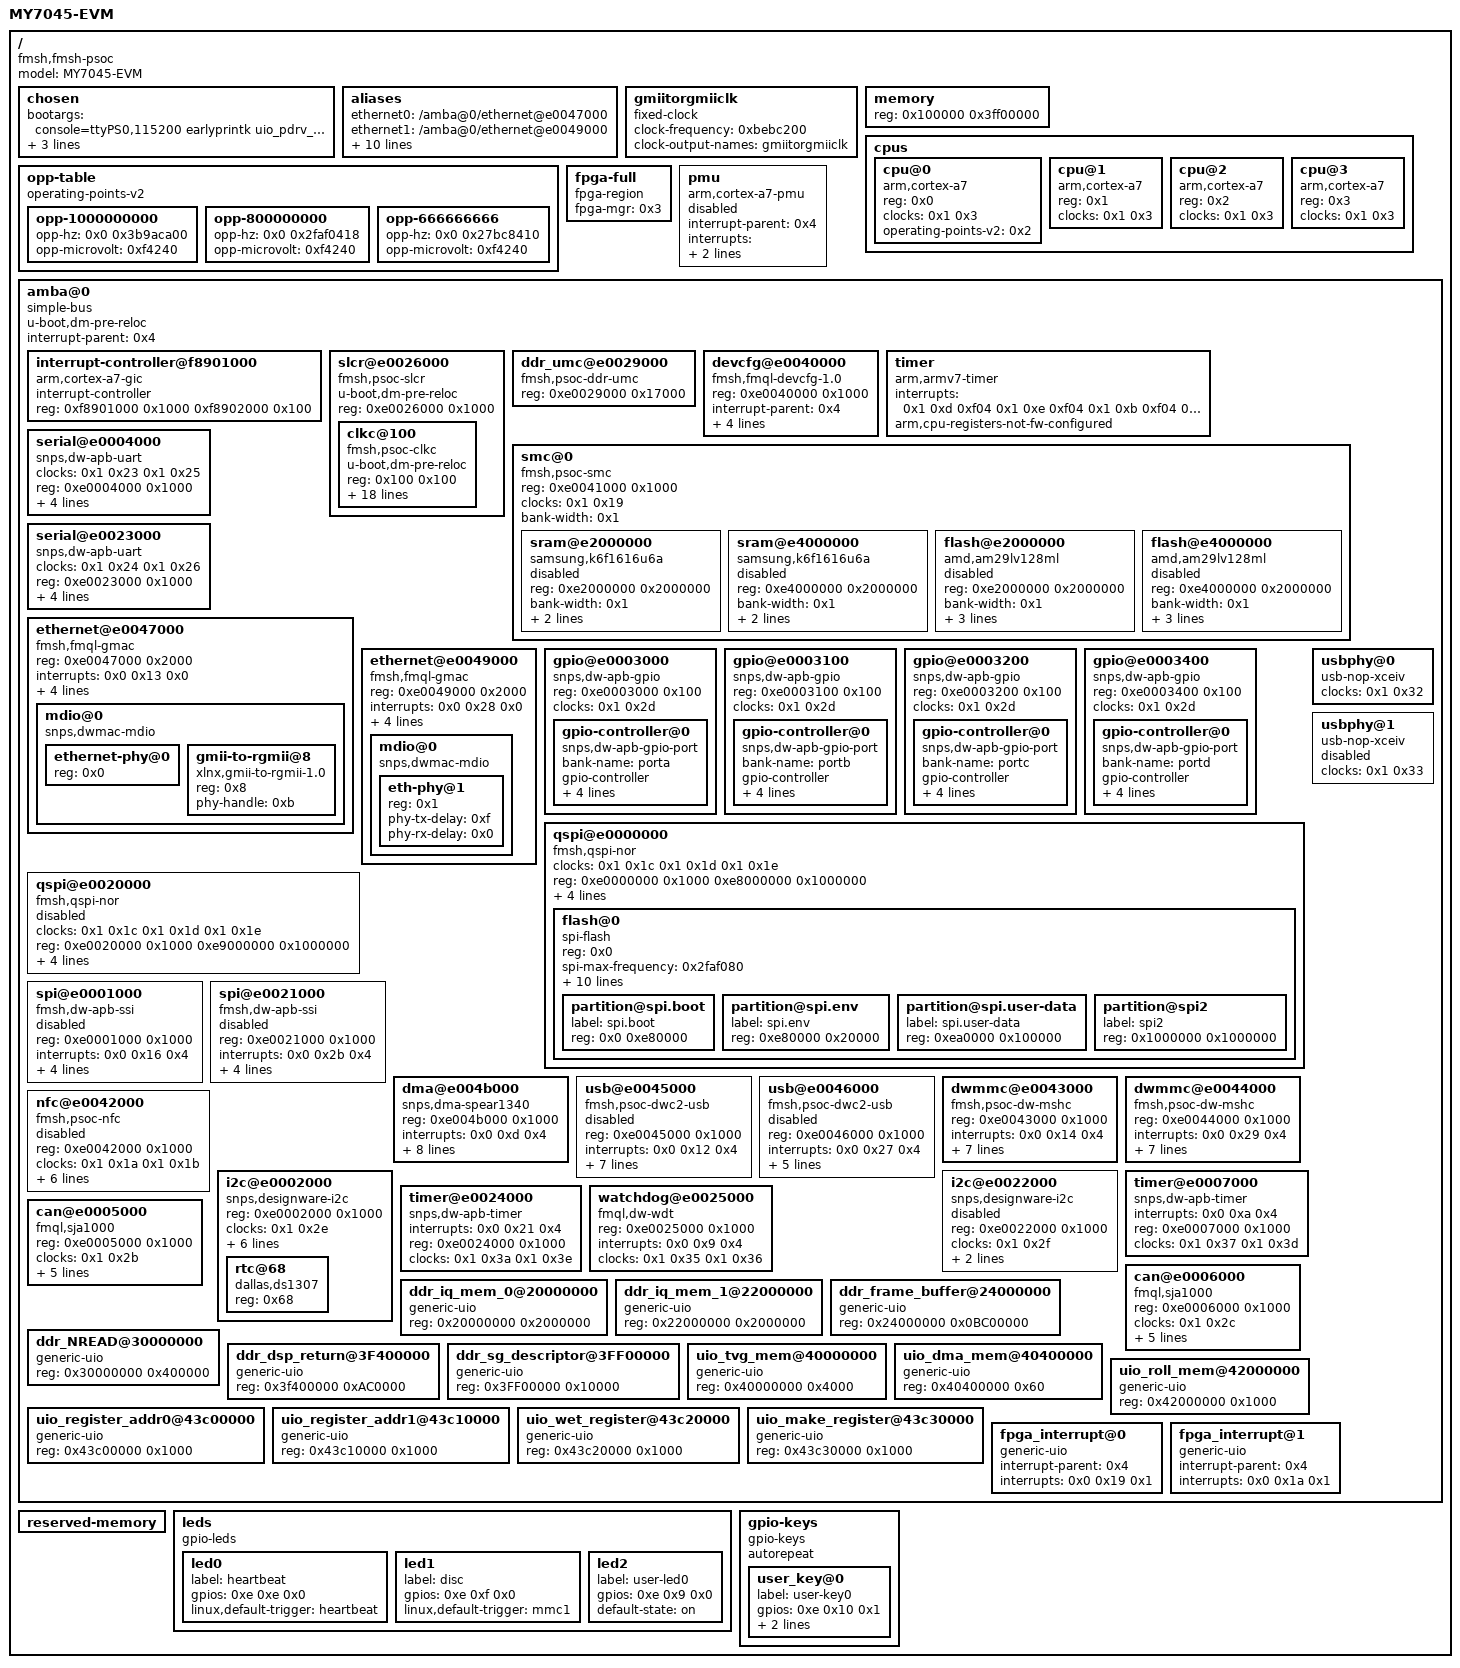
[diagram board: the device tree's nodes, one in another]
/dts-v1/;

/ {
	#address-cells = <0x1>;
	#size-cells = <0x1>;
	model = "MY7045-EVM";
	compatible = "fmsh,fmsh-psoc";

	chosen {
		bootargs = "console=ttyPS0,115200 earlyprintk uio_pdrv_genirq.of_id=generic-uio loglevel=8 root=/dev/mmcblk0p2 rw";
		stdout-path = "serial0:115200n8";
		linux,initrd-start = <0x12000000>;
		linux,initrd-end = <0x12800000>;
	};

	aliases {
		ethernet0 = "/amba@0/ethernet@e0047000";
		ethernet1 = "/amba@0/ethernet@e0049000";
		serial0 = "/amba@0/serial@e0023000";
		serial1 = "/amba@0/serial@e0004000";
		spi0 = "/amba@0/qspi@e0000000";
		spi1 = "/amba@0/qspi@e0020000";
		spi2 = "/amba@0/spi@e0001000";
		spi3 = "/amba@0/spi@e0021000";
		mmc0 = "/amba@0/dwmmc@e0043000";
		mmc1 = "/amba@0/dwmmc@e0044000";
		i2c0 = "/amba@0/i2c@e0002000";
		i2c1 = "/amba@0/i2c@e0022000";
	};

	gmiitorgmiiclk {
		compatible = "fixed-clock";
		#clock-cells = <0x0>;
		clock-frequency = <0xbebc200>;
		clock-output-names = "gmiitorgmiiclk";
	};

	memory {
		device_type = "memory";
		reg = <0x100000 0x3ff00000>;
	};

	cpus {
		#address-cells = <0x1>;
		#size-cells = <0x0>;

		cpu@0 {
			compatible = "arm,cortex-a7";
			device_type = "cpu";
			reg = <0x0>;
			clocks = <0x1 0x3>;
			operating-points-v2 = <0x2>;
			linux,phandle = <0x5>;
			phandle = <0x5>;
		};

		cpu@1 {
			compatible = "arm,cortex-a7";
			device_type = "cpu";
			reg = <0x1>;
			clocks = <0x1 0x3>;
			linux,phandle = <0x6>;
			phandle = <0x6>;
		};

		cpu@2 {
			compatible = "arm,cortex-a7";
			device_type = "cpu";
			reg = <0x2>;
			clocks = <0x1 0x3>;
			linux,phandle = <0x7>;
			phandle = <0x7>;
		};

		cpu@3 {
			compatible = "arm,cortex-a7";
			device_type = "cpu";
			reg = <0x3>;
			clocks = <0x1 0x3>;
			linux,phandle = <0x8>;
			phandle = <0x8>;
		};
	};

	opp-table {
		compatible = "operating-points-v2";
		linux,phandle = <0x2>;
		phandle = <0x2>;

		opp-1000000000 {
			opp-hz = <0x0 0x3b9aca00>;
			opp-microvolt = <0xf4240>;
		};

		opp-800000000 {
			opp-hz = <0x0 0x2faf0418>;
			opp-microvolt = <0xf4240>;
		};

		opp-666666666 {
			opp-hz = <0x0 0x27bc8410>;
			opp-microvolt = <0xf4240>;
		};
	};

	fpga-full {
		compatible = "fpga-region";
		fpga-mgr = <0x3>;
		#address-cells = <0x1>;
		#size-cells = <0x1>;
		ranges;
		linux,phandle = <0xf>;
		phandle = <0xf>;
	};

	pmu {
		compatible = "arm,cortex-a7-pmu";
		interrupt-parent = <0x4>;
		interrupts = <0x0 0x4 0x4 0x0 0x5 0x4 0x0 0x6 0x4 0x0 0x7 0x4>;
		interrupt-affinity = <0x5 0x6 0x7 0x8>;
		status = "disabled";
	};

	amba@0 {
		u-boot,dm-pre-reloc;
		compatible = "simple-bus";
		#address-cells = <0x1>;
		#size-cells = <0x1>;
		interrupt-parent = <0x4>;
		ranges;
		linux,phandle = <0x10>;
		phandle = <0x10>;

		interrupt-controller@f8901000 {
			compatible = "arm,cortex-a7-gic";
			#interrupt-cells = <0x3>;
			#address-cells = <0x1>;
			interrupt-controller;
			reg = <0xf8901000 0x1000 0xf8902000 0x100>;
			linux,phandle = <0x4>;
			phandle = <0x4>;
		};

		slcr@e0026000 {
			u-boot,dm-pre-reloc;
			#address-cells = <0x1>;
			#size-cells = <0x1>;
			compatible = "fmsh,psoc-slcr", "syscon", "simple-mfd";
			reg = <0xe0026000 0x1000>;
			ranges;
			linux,phandle = <0x9>;
			phandle = <0x9>;

			clkc@100 {
				u-boot,dm-pre-reloc;
				compatible = "fmsh,psoc-clkc";
				reg = <0x100 0x100>;
				#clock-cells = <0x1>;
				ps-clk-frequency = <0x1fca055>;
				osc-clk-frequency = <0x7ffd>;
				fclk-enable = <0x0>;
				clock-output-names = "armpll", "ddrpll", "iopll", "cpu", "axi", "ahb", "apb", "axi_cpu", "ddrx1", "ddrx4", "axi_ddr", "apb_ddr", "gtimer", "gmac0_tx", "gmac1_tx", "fclk0", "fclk1", "fclk2", "fclk3", "gmac0_rx", "gmac1_rx", "axi_gmac0", "axi_gmac1", "ahb_gmac0", "ahb_gmac1", "ahb_smc", "ahb_nfc", "nfc", "qspi", "ahb_qspi", "apb_qspi", "sdio0", "sdio1", "ahb_sdio0", "ahb_sdio1", "uart0", "uart1", "apb_uart0", "apb_uart1", "spi0", "spi1", "apb_spi0", "apb_spi1", "apb_can0", "apb_can1", "apb_gpio", "apb_i2c0", "apb_i2c1", "ahb_usb0", "ahb_usb1", "usb0_phy", "usb1_phy", "ahb_dmac", "wdt", "apb_wdt", "ttc0_ref1", "ttc0_ref2", "ttc0_ref3", "ttc1_ref1", "ttc1_ref2", "ttc1_ref3", "apb_ttc0", "apb_ttc1", "ahb_pcap";
				linux,phandle = <0x1>;
				phandle = <0x1>;
			};
		};

		ddr_umc@e0029000 {
			compatible = "fmsh,psoc-ddr-umc", "syscon", "simple-mfd";
			#address-cells = <0x1>;
			#size-cells = <0x1>;
			reg = <0xe0029000 0x17000>;
			linux,phandle = <0xa>;
			phandle = <0xa>;
		};

		devcfg@e0040000 {
			compatible = "fmsh,fmql-devcfg-1.0";
			reg = <0xe0040000 0x1000>;
			interrupt-parent = <0x4>;
			interrupts = <0x0 0x8 0x4>;
			clocks = <0x1 0x3f>;
			clock-names = "ref_clk";
			syscon = <0x9>;
			ddrcon = <0xa>;
			status = "okay";
			linux,phandle = <0x3>;
			phandle = <0x3>;
		};

		timer {
			compatible = "arm,armv7-timer";
			interrupts = <0x1 0xd 0xf04 0x1 0xe 0xf04 0x1 0xb 0xf04 0x1 0xa 0xf04>;
			arm,cpu-registers-not-fw-configured;
			status = "okay";
			linux,phandle = <0x11>;
			phandle = <0x11>;
		};

		smc@0 {
			compatible = "fmsh,psoc-smc", "simple-bus";
			reg = <0xe0041000 0x1000>;
			clocks = <0x1 0x19>;
			#address-cells = <0x1>;
			#size-cells = <0x1>;
			bank-width = <0x1>;
			ranges;
			linux,phandle = <0x12>;
			phandle = <0x12>;

			sram@e2000000 {
				compatible = "samsung,k6f1616u6a", "mtd-ram";
				reg = <0xe2000000 0x2000000>;
				#address-cells = <0x1>;
				#size-cells = <0x1>;
				bank-width = <0x1>;
				fmsh,smc-type = "sram";
				fmsh,smc-cs = <0x0>;
				status = "disabled";
				linux,phandle = <0x13>;
				phandle = <0x13>;
			};

			sram@e4000000 {
				compatible = "samsung,k6f1616u6a", "mtd-ram";
				reg = <0xe4000000 0x2000000>;
				#address-cells = <0x1>;
				#size-cells = <0x1>;
				bank-width = <0x1>;
				fmsh,smc-type = "sram";
				fmsh,smc-cs = <0x1>;
				status = "disabled";
				linux,phandle = <0x14>;
				phandle = <0x14>;
			};

			flash@e2000000 {
				compatible = "amd,am29lv128ml", "cfi-flash";
				reg = <0xe2000000 0x2000000>;
				bank-width = <0x1>;
				device-width = <0x1>;
				#address-cells = <0x1>;
				#size-cells = <0x1>;
				fmsh,smc-type = "flash";
				fmsh,smc-cs = <0x0>;
				status = "disabled";
				linux,phandle = <0x15>;
				phandle = <0x15>;
			};

			flash@e4000000 {
				compatible = "amd,am29lv128ml", "cfi-flash";
				reg = <0xe4000000 0x2000000>;
				bank-width = <0x1>;
				device-width = <0x1>;
				#address-cells = <0x1>;
				#size-cells = <0x1>;
				fmsh,smc-type = "flash";
				fmsh,smc-cs = <0x1>;
				status = "disabled";
				linux,phandle = <0x16>;
				phandle = <0x16>;
			};
		};

		serial@e0004000 {
			compatible = "snps,dw-apb-uart";
			clocks = <0x1 0x23 0x1 0x25>;
			clock-names = "baudclk", "apb_pclk";
			reg = <0xe0004000 0x1000>;
			interrupts = <0x0 0x17 0x4>;
			reg-shift = <0x2>;
			reg-io-width = <0x4>;
			u-boot,dm-pre-reloc;
			status = "okay";
			linux,phandle = <0x17>;
			phandle = <0x17>;
		};

		serial@e0023000 {
			compatible = "snps,dw-apb-uart";
			clocks = <0x1 0x24 0x1 0x26>;
			clock-names = "baudclk", "apb_pclk";
			reg = <0xe0023000 0x1000>;
			interrupts = <0x0 0x2c 0x4>;
			reg-shift = <0x2>;
			reg-io-width = <0x4>;
			u-boot,dm-pre-reloc;
			status = "okay";
			linux,phandle = <0x18>;
			phandle = <0x18>;
		};

		ethernet@e0047000 {
			compatible = "fmsh,fmql-gmac", "snps,dwmac-3.70a", "snps,dwmac";
			reg = <0xe0047000 0x2000>;
			reg-names = "stmmaceth";
			interrupts = <0x0 0x13 0x0>;
			interrupt-names = "macirq";
			mac-address = [00 01 02 03 04 05];
			clocks = <0x1 0x17 0x1 0x15 0x1 0xd 0x1 0x13>;
			clock-names = "stmmaceth", "pclk", "fmql-gmac-tx", "fmql-gmac-rx";
			phy-mode = "rgmii-rxid";
			status = "okay";
			phy-handle = <0xb>;

			mdio@0 {
				compatible = "snps,dwmac-mdio";
				#address-cells = <0x1>;
				#size-cells = <0x0>;

				ethernet-phy@0 {
					reg = <0x0>;
					linux,phandle = <0xb>;
					phandle = <0xb>;
				};

				gmii-to-rgmii@8 {
					compatible = "xlnx,gmii-to-rgmii-1.0";
					reg = <0x8>;
					phy-handle = <0xb>;
				};
			};
		};

		ethernet@e0049000 {
			compatible = "fmsh,fmql-gmac", "snps,dwmac-3.70a", "snps,dwmac";
			reg = <0xe0049000 0x2000>;
			reg-names = "stmmaceth";
			interrupts = <0x0 0x28 0x0>;
			interrupt-names = "macirq";
			mac-address = [00 01 02 03 04 06];
			clocks = <0x1 0x18 0x1 0x16 0x1 0xe 0x1 0x14>;
			clock-names = "stmmaceth", "pclk", "fmql-gmac-tx", "fmql-gmac-rx";
			phy-mode = "rgmii-id";
			status = "okay";
			phy-handle = <0x19>;

			mdio@0 {
				compatible = "snps,dwmac-mdio";
				#address-cells = <0x1>;
				#size-cells = <0x0>;

				eth-phy@1 {
					reg = <0x1>;
					phy-tx-delay = <0xf>;
					phy-rx-delay = <0x0>;
					linux,phandle = <0x19>;
					phandle = <0x19>;
				};
			};
		};

		gpio@e0003000 {
			compatible = "snps,dw-apb-gpio";
			reg = <0xe0003000 0x100>;
			#address-cells = <0x1>;
			#size-cells = <0x0>;
			clocks = <0x1 0x2d>;
			status = "okay";
			linux,phandle = <0x1b>;
			phandle = <0x1b>;

			gpio-controller@0 {
				compatible = "snps,dw-apb-gpio-port";
				bank-name = "porta";
				gpio-controller;
				#gpio-cells = <0x2>;
				snps,nr-gpios = <0x20>;
				reg = <0x0>;
				interrupt-controller;
				#interrupt-cells = <0x2>;
				interrupts = <0x0 0x11 0x4>;
				linux,phandle = <0xe>;
				phandle = <0xe>;
			};
		};

		gpio@e0003100 {
			compatible = "snps,dw-apb-gpio";
			reg = <0xe0003100 0x100>;
			#address-cells = <0x1>;
			#size-cells = <0x0>;
			clocks = <0x1 0x2d>;
			status = "okay";
			linux,phandle = <0x1c>;
			phandle = <0x1c>;

			gpio-controller@0 {
				compatible = "snps,dw-apb-gpio-port";
				bank-name = "portb";
				gpio-controller;
				#gpio-cells = <0x2>;
				snps,nr-gpios = <0x16>;
				reg = <0x0>;
				interrupt-controller;
				#interrupt-cells = <0x2>;
				interrupts = <0x0 0x24 0x4>;
				linux,phandle = <0x1d>;
				phandle = <0x1d>;
			};
		};

		gpio@e0003200 {
			compatible = "snps,dw-apb-gpio";
			reg = <0xe0003200 0x100>;
			#address-cells = <0x1>;
			#size-cells = <0x0>;
			clocks = <0x1 0x2d>;
			status = "okay";
			linux,phandle = <0x1e>;
			phandle = <0x1e>;

			gpio-controller@0 {
				compatible = "snps,dw-apb-gpio-port";
				bank-name = "portc";
				gpio-controller;
				#gpio-cells = <0x2>;
				snps,nr-gpios = <0x20>;
				reg = <0x0>;
				interrupt-controller;
				#interrupt-cells = <0x2>;
				interrupts = <0x0 0x25 0x4>;
				linux,phandle = <0x1f>;
				phandle = <0x1f>;
			};
		};

		gpio@e0003400 {
			compatible = "snps,dw-apb-gpio";
			reg = <0xe0003400 0x100>;
			#address-cells = <0x1>;
			#size-cells = <0x0>;
			clocks = <0x1 0x2d>;
			status = "okay";
			linux,phandle = <0x20>;
			phandle = <0x20>;

			gpio-controller@0 {
				compatible = "snps,dw-apb-gpio-port";
				bank-name = "portd";
				gpio-controller;
				#gpio-cells = <0x2>;
				snps,nr-gpios = <0x20>;
				reg = <0x0>;
				interrupt-controller;
				#interrupt-cells = <0x2>;
				interrupts = <0x0 0x26 0x4>;
				linux,phandle = <0x21>;
				phandle = <0x21>;
			};
		};

		qspi@e0000000 {
			compatible = "fmsh,qspi-nor", "cadence,qspi";
			clocks = <0x1 0x1c 0x1 0x1d 0x1 0x1e>;
			clock-names = "clk_ref", "hclk", "pclk";
			#address-cells = <0x1>;
			#size-cells = <0x0>;
			reg = <0xe0000000 0x1000 0xe8000000 0x1000000>;
			interrupts = <0x0 0xe 0x4>;
			cdns,fifo-depth = <0x100>;
			cdns,fifo-width = <0x4>;
			cdns,trigger-address = <0xe8000000>;
			status = "okay";
			linux,phandle = <0x22>;
			phandle = <0x22>;

			flash@0 {
				compatible = "spi-flash", "spansion,s25fl256s1", "jedec,spi-nor";
				reg = <0x0>;
				spi-max-frequency = <0x2faf080>;
				spi-tx-bus-width = <0x1>;
				spi-rx-bus-width = <0x4>;
				m25p,fast-read;
				page-size = <0x100>;
				block-size = <0x10>;
				cdns,read-delay = <0x2>;
				cdns,tshsl-ns = <0x0>;
				cdns,tsd2d-ns = <0x0>;
				cdns,tchsh-ns = <0x0>;
				cdns,tslch-ns = <0x0>;
				#address-cells = <0x1>;
				#size-cells = <0x1>;
				linux,phandle = <0x23>;
				phandle = <0x23>;

				partition@spi.boot {
					label = "spi.boot";
					reg = <0x0 0xe80000>;
				};

				partition@spi.env {
					label = "spi.env";
					reg = <0xe80000 0x20000>;
				};

				partition@spi.user-data {
					label = "spi.user-data";
					reg = <0xea0000 0x100000>;
				};

				partition@spi2 {
					label = "spi2";
					reg = <0x1000000 0x1000000>;
				};
			};
		};

		qspi@e0020000 {
			compatible = "fmsh,qspi-nor", "cadence,qspi";
			clocks = <0x1 0x1c 0x1 0x1d 0x1 0x1e>;
			clock-names = "clk_ref", "hclk", "pclk";
			#address-cells = <0x1>;
			#size-cells = <0x0>;
			reg = <0xe0020000 0x1000 0xe9000000 0x1000000>;
			interrupts = <0x0 0xf 0x4>;
			cdns,fifo-depth = <0x100>;
			cdns,fifo-width = <0x4>;
			cdns,trigger-address = <0xe9000000>;
			status = "disabled";
			linux,phandle = <0x24>;
			phandle = <0x24>;
		};

		spi@e0001000 {
			compatible = "fmsh,dw-apb-ssi", "snps,dw-apb-ssi";
			#address-cells = <0x1>;
			#size-cells = <0x0>;
			reg = <0xe0001000 0x1000>;
			interrupts = <0x0 0x16 0x4>;
			num-cs = <0x3>;
			clocks = <0x1 0x27 0x1 0x29>;
			clock-names = "clk_ref", "pclk";
			reg-io-width = <0x4>;
			spi-max-frequency = <0xf4240>;
			status = "disabled";
			linux,phandle = <0x25>;
			phandle = <0x25>;
		};

		spi@e0021000 {
			compatible = "fmsh,dw-apb-ssi", "snps,dw-apb-ssi";
			#address-cells = <0x1>;
			#size-cells = <0x0>;
			reg = <0xe0021000 0x1000>;
			interrupts = <0x0 0x2b 0x4>;
			num-cs = <0x3>;
			clocks = <0x1 0x28 0x1 0x2a>;
			clock-names = "clk_ref", "pclk";
			reg-io-width = <0x4>;
			spi-max-frequency = <0xf4240>;
			status = "disabled";
			linux,phandle = <0x26>;
			phandle = <0x26>;
		};

		dma@e004b000 {
			compatible = "snps,dma-spear1340";
			reg = <0xe004b000 0x1000>;
			interrupts = <0x0 0xd 0x4>;
			dma-channels = <0x8>;
			dma-requests = <0x10>;
			dma-masters = <0x1>;
			#dma-cells = <0x3>;
			chan_allocation_order = <0x1>;
			chan_priority = <0x1>;
			block_size = <0xfff>;
			data-width = <0x4>;
			clocks = <0x1 0x34>;
			clock-names = "hclk";
			status = "okay";
			linux,phandle = <0x27>;
			phandle = <0x27>;
		};

		usbphy@0 {
			compatible = "usb-nop-xceiv";
			#phy-cells = <0x0>;
			clocks = <0x1 0x32>;
			clock-names = "main_clk";
			status = "okay";
			linux,phandle = <0xc>;
			phandle = <0xc>;
		};

		usbphy@1 {
			compatible = "usb-nop-xceiv";
			#phy-cells = <0x0>;
			clocks = <0x1 0x33>;
			clock-names = "main_clk";
			status = "disabled";
			linux,phandle = <0xd>;
			phandle = <0xd>;
		};

		usb@e0045000 {
			compatible = "fmsh,psoc-dwc2-usb", "snps,dwc2";
			reg = <0xe0045000 0x1000>;
			interrupts = <0x0 0x12 0x4>;
			clocks = <0x1 0x30>;
			clock-names = "otg";
			#address-cells = <0x1>;
			#size-cells = <0x0>;
			phys = <0xc>;
			phy-names = "usb2-phy";
			dr_mode = "peripheral";
			phy-width = <0x8>;
			fmql,host_dma = <0x1>;
			status = "disable";
			disable-over-current;
			hnp-srp-disable;
			linux,phandle = <0x28>;
			phandle = <0x28>;
		};

		usb@e0046000 {
			compatible = "fmsh,psoc-dwc2-usb", "snps,dwc2";
			reg = <0xe0046000 0x1000>;
			interrupts = <0x0 0x27 0x4>;
			clocks = <0x1 0x31>;
			clock-names = "otg";
			#address-cells = <0x1>;
			#size-cells = <0x0>;
			phys = <0xd>;
			phy-names = "usb2-phy";
			dr_mode = "otg";
			phy-width = <0x8>;
			fmql,host_dma = <0x0>;
			status = "disabled";
			linux,phandle = <0x29>;
			phandle = <0x29>;
		};

		dwmmc@e0043000 {
			compatible = "fmsh,psoc-dw-mshc";
			reg = <0xe0043000 0x1000>;
			interrupts = <0x0 0x14 0x4>;
			clocks = <0x1 0x21 0x1 0x1f>;
			clock-names = "biu", "ciu";
			#address-cells = <0x1>;
			#size-cells = <0x0>;
			data-addr = <0x100>;
			fifo-depth = <0x20>;
			bus-width = <0x4>;
			status = "okay";
			cap-sd-highspeed;
			cap-mmc-highspeed;
			max-frequency = <0x1312d00>;
			linux,phandle = <0x2a>;
			phandle = <0x2a>;
		};

		dwmmc@e0044000 {
			compatible = "fmsh,psoc-dw-mshc";
			reg = <0xe0044000 0x1000>;
			interrupts = <0x0 0x29 0x4>;
			clocks = <0x1 0x22 0x1 0x20>;
			clock-names = "biu", "ciu";
			#address-cells = <0x1>;
			#size-cells = <0x0>;
			data-addr = <0x100>;
			fifo-depth = <0x20>;
			bus-width = <0x4>;
			status = "okay";
			cap-sd-highspeed;
			cap-mmc-highspeed;
			broken-cd;
			linux,phandle = <0x2b>;
			phandle = <0x2b>;
		};

		nfc@e0042000 {
			compatible = "fmsh,psoc-nfc";
			reg = <0xe0042000 0x1000>;
			clocks = <0x1 0x1a 0x1 0x1b>;
			clock-names = "pclk", "nfc_ref";
			#address-cells = <0x1>;
			#size-cells = <0x1>;
			interrupts = <0x0 0x10 0x4>;
			nand-bus-width = <0x8>;
			nand-ecc-mode = "hw";
			nand-ecc-strength = <0x8>;
			nand-ecc-step-size = <0x200>;
			nand-use-mode = "dma";
			status = "disabled";
			linux,phandle = <0x2c>;
			phandle = <0x2c>;
		};

		i2c@e0002000 {
			compatible = "snps,designware-i2c";
			reg = <0xe0002000 0x1000>;
			#address-cells = <0x1>;
			#size-cells = <0x0>;
			clocks = <0x1 0x2e>;
			interrupts = <0x0 0x15 0x4>;
			i2c-max-frequency = <0xf4240>;
			status = "okay";
			clock-frequency = <0x186a0>;
			i2c-sda-hold-time-ns = <0x12c>;
			i2c-sda-falling-time-ns = <0x12c>;
			i2c-scl-falling-time-ns = <0x12c>;
			linux,phandle = <0x2d>;
			phandle = <0x2d>;

			rtc@68 {
				compatible = "dallas,ds1307";
				reg = <0x68>;
				linux,phandle = <0x2e>;
				phandle = <0x2e>;
			};
		};

		i2c@e0022000 {
			compatible = "snps,designware-i2c";
			reg = <0xe0022000 0x1000>;
			clocks = <0x1 0x2f>;
			interrupts = <0x0 0x2a 0x4>;
			#address-cells = <0x1>;
			#size-cells = <0x0>;
			i2c-max-frequency = <0xf4240>;
			status = "disabled";
			linux,phandle = <0x2f>;
			phandle = <0x2f>;
		};

		timer@e0007000 {
			compatible = "snps,dw-apb-timer";
			interrupts = <0x0 0xa 0x4>;
			reg = <0xe0007000 0x1000>;
			clocks = <0x1 0x37 0x1 0x3d>;
			clock-names = "timer", "pclk";
			linux,phandle = <0x30>;
			phandle = <0x30>;
		};

		timer@e0024000 {
			compatible = "snps,dw-apb-timer";
			interrupts = <0x0 0x21 0x4>;
			reg = <0xe0024000 0x1000>;
			clocks = <0x1 0x3a 0x1 0x3e>;
			clock-names = "timer", "pclk";
			linux,phandle = <0x31>;
			phandle = <0x31>;
		};

		watchdog@e0025000 {
			compatible = "fmql,dw-wdt";
			reg = <0xe0025000 0x1000>;
			interrupts = <0x0 0x9 0x4>;
			clocks = <0x1 0x35 0x1 0x36>;
			clock-names = "wdt", "pclk";
			status = "okay";
			linux,phandle = <0x32>;
			phandle = <0x32>;
		};

		can@e0005000 {
			compatible = "fmql,sja1000";
			reg = <0xe0005000 0x1000>;
			clocks = <0x1 0x2b>;
			clock-names = "pclk";
			interrupts = <0x0 0x18 0x4>;
			reg-io-width = <0x4>;
			nxp,tx-output-mode = <0x1>;
			nxp,tx-output-config = <0x2>;
			nxp,no-comparator-bypass;
			status = "okay";
			linux,phandle = <0x33>;
			phandle = <0x33>;
		};

		can@e0006000 {
			compatible = "fmql,sja1000";
			reg = <0xe0006000 0x1000>;
			clocks = <0x1 0x2c>;
			clock-names = "pclk";
			interrupts = <0x0 0x2d 0x4>;
			reg-io-width = <0x4>;
			nxp,tx-output-mode = <0x1>;
			nxp,tx-output-config = <0x2>;
			nxp,no-comparator-bypass;
			status = "okay";
			linux,phandle = <0x34>;
			phandle = <0x34>;
		};

		ddr_iq_mem_0@20000000 {
			compatible = "generic-uio";
			reg = <0x20000000 0x2000000>;
			status = "okay";
		};

		ddr_iq_mem_1@22000000 {
			compatible = "generic-uio";
			reg = <0x22000000 0x2000000>;
			status = "okay";
		};

		ddr_frame_buffer@24000000 {
			compatible = "generic-uio";
			reg = <0x24000000 0x0BC00000>;
			status = "okay";
		};

		ddr_NREAD@30000000 {
			compatible = "generic-uio";
			reg = <0x30000000 0x400000>;
			status = "okay";
		};

		ddr_dsp_return@3F400000 {
			compatible = "generic-uio";
			reg = <0x3f400000 0xAC0000>;
			status = "okay";
		};

		ddr_sg_descriptor@3FF00000 {
			compatible = "generic-uio";
			reg = <0x3FF00000 0x10000>;
			status = "okay";
		};

		uio_tvg_mem@40000000 {
			compatible = "generic-uio";
			reg = <0x40000000 0x4000>;
			status = "okay";
		};

		uio_dma_mem@40400000{
			compatible = "generic-uio";
			reg = <0x40400000 0x60>;
			status = "okay";
		};

		uio_roll_mem@42000000 {
			compatible = "generic-uio";
			reg = <0x42000000 0x1000>;
			status = "okay";
		};

		uio_register_addr0@43c00000 {
			compatible = "generic-uio";
			reg = <0x43c00000 0x1000>;
			status = "okay";
		};

		uio_register_addr1@43c10000 {
			compatible = "generic-uio";
			reg = <0x43c10000 0x1000>;
			status = "okay";
		};

		uio_wet_register@43c20000 {
			compatible = "generic-uio";
			reg = <0x43c20000 0x1000>;
			status = "okay";
		};

		uio_make_register@43c30000 {
			compatible = "generic-uio";
			reg = <0x43c30000 0x1000>;
			status = "okay";
		};

		fpga_interrupt@0 {
			compatible = "generic-uio";
			interrupt-parent = <0x4>;
			interrupts = <0x0 0x19 0x1>;
			status = "okay";
		};

		fpga_interrupt@1 {
			compatible = "generic-uio";
			interrupt-parent = <0x4>;
			interrupts = <0x0 0x1a 0x1>;
			status = "okay";
		};
	};

	reserved-memory {
		#address-cells = <0x1>;
		#size-cells = <0x1>;
		ranges;
	};

	leds {
		compatible = "gpio-leds";

		led0 {
			label = "heartbeat";
			gpios = <0xe 0xe 0x0>;
			linux,default-trigger = "heartbeat";
		};

		led1 {
			label = "disc";
			gpios = <0xe 0xf 0x0>;
			linux,default-trigger = "mmc1";
		};

		led2 {
			label = "user-led0";
			gpios = <0xe 0x9 0x0>;
			default-state = "on";
		};
	};

	gpio-keys {
		compatible = "gpio-keys";
		#address-cells = <0x1>;
		#size-cells = <0x0>;
		autorepeat;

		user_key@0 {
			label = "user-key0";
			gpios = <0xe 0x10 0x1>;
			linux,code = <0x94>;
			debounce-interval = <0x0>;
		};
	};

	__symbols__ {
		cpu0 = "/cpus/cpu@0";
		cpu1 = "/cpus/cpu@1";
		cpu2 = "/cpus/cpu@2";
		cpu3 = "/cpus/cpu@3";
		cpu0_opp_table = "/opp-table";
		fpga_full = "/fpga-full";
		amba = "/amba@0";
		intc = "/amba@0/interrupt-controller@f8901000";
		slcr = "/amba@0/slcr@e0026000";
		clkc = "/amba@0/slcr@e0026000/clkc@100";
		ddr_umc = "/amba@0/ddr_umc@e0029000";
		devcfg = "/amba@0/devcfg@e0040000";
		timer = "/amba@0/timer";
		smc = "/amba@0/smc@0";
		sram0 = "/amba@0/smc@0/sram@e2000000";
		sram1 = "/amba@0/smc@0/sram@e4000000";
		nor0 = "/amba@0/smc@0/flash@e2000000";
		nor1 = "/amba@0/smc@0/flash@e4000000";
		uart0 = "/amba@0/serial@e0004000";
		uart1 = "/amba@0/serial@e0023000";
		gmac0 = "/amba@0/ethernet@e0047000";
		gmac1 = "/amba@0/ethernet@e0049000";
		phy1 = "/amba@0/ethernet@e0049000/mdio@0/eth-phy@1";
		gpio0 = "/amba@0/gpio@e0003000";
		porta = "/amba@0/gpio@e0003000/gpio-controller@0";
		gpio1 = "/amba@0/gpio@e0003100";
		portb = "/amba@0/gpio@e0003100/gpio-controller@0";
		gpio2 = "/amba@0/gpio@e0003200";
		portc = "/amba@0/gpio@e0003200/gpio-controller@0";
		gpio3 = "/amba@0/gpio@e0003400";
		portd = "/amba@0/gpio@e0003400/gpio-controller@0";
		qspi0 = "/amba@0/qspi@e0000000";
		flash = "/amba@0/qspi@e0000000/flash@0";
		qspi1 = "/amba@0/qspi@e0020000";
		spi0 = "/amba@0/spi@e0001000";
		spi1 = "/amba@0/spi@e0021000";
		dmahost = "/amba@0/dma@e004b000";
		usbphy0 = "/amba@0/usbphy@0";
		usbphy1 = "/amba@0/usbphy@1";
		usb0 = "/amba@0/usb@e0045000";
		usb1 = "/amba@0/usb@e0046000";
		mmc0 = "/amba@0/dwmmc@e0043000";
		mmc1 = "/amba@0/dwmmc@e0044000";
		nand = "/amba@0/nfc@e0042000";
		i2c0 = "/amba@0/i2c@e0002000";
		ds1307 = "/amba@0/i2c@e0002000/rtc@68";
		i2c1 = "/amba@0/i2c@e0022000";
		timer1 = "/amba@0/timer@e0007000";
		timer2 = "/amba@0/timer@e0024000";
		watchdog = "/amba@0/watchdog@e0025000";
		can0 = "/amba@0/can@e0005000";
		can1 = "/amba@0/can@e0006000";
	};
};
